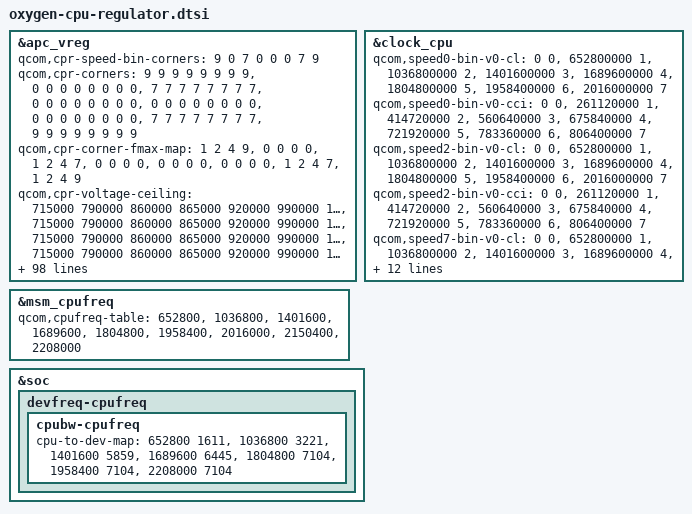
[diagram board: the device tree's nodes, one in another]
/* Copyright (c) 2020, The Linux Foundation. All rights reserved.
*  Copyright (c) 2020, Jebaitedneko.
*
* This program is free software; you can redistribute it and/or modify
* it under the terms of the GNU General Public License version 2 and
* only version 2 as published by the Free Software Foundation.
*
* This program is distributed in the hope that it will be useful,
* but WITHOUT ANY WARRANTY; without even the implied warranty of
* MERCHANTABILITY or FITNESS FOR A PARTICULAR PURPOSE.  See the
* GNU General Public License for more details.
*/

&apc_vreg {
	qcom,cpr-speed-bin-corners =
		<9 0 7 0 0 0 7 9>;
	qcom,cpr-corners =
		/* Speed bin 0 */
		<9 9 9 9 9 9 9 9>,

		/* Speed bin 1 */
		<0 0 0 0 0 0 0 0>,

		/* Speed bin 2 */
		<7 7 7 7 7 7 7 7>,

		/* Speed bin 3..5 */
		<0 0 0 0 0 0 0 0>,
		<0 0 0 0 0 0 0 0>,
		<0 0 0 0 0 0 0 0>,

		/* Speed bin 6 */
		<7 7 7 7 7 7 7 7>,

		/* Speed bin 7 */
		<9 9 9 9 9 9 9 9>;

	qcom,cpr-corner-fmax-map =
		/* Speed bin 0 */
		<1 2 4 9>,

		/* Speed bin 1 */
		<0 0 0 0>,

		/* Speed bin 2 */
		<1 2 4 7>,

		/* Speed bin 3..5 */
		<0 0 0 0>,
		<0 0 0 0>,
		<0 0 0 0>,

		/* Speed bin 6 */
		<1 2 4 7>,

		/* Speed bin 7 */
		<1 2 4 9>;

	qcom,cpr-voltage-ceiling =
		/* Speed bin 0 */
		<715000  790000 860000 865000 920000
			990000 1065000 1065000 1065000>,

		/* Speed bin 2 */
		<715000  790000 860000 865000 920000
			990000 1065000>,

		/* Speed bin 6 */
		<715000  790000 860000 865000 920000
			990000 1065000>,

		/* Speed bin 7 */
		<715000  790000 860000 865000 920000
			990000 1065000 1065000 1065000>;

	qcom,cpr-voltage-floor =
		/* Speed bin 0 */
		<500000  500000 500000 500000 500000
			500000  500000 500000 500000>,

		/* Speed bin 2 */
		<500000  500000 500000 500000 500000
			500000  500000>,

		/* Speed bin 6 */
		<500000  500000 500000 500000 500000
			500000  500000>,

		/* Speed bin 7 */
		<500000  500000 500000 500000 500000
			500000  500000 500000 500000>;

	qcom,cpr-floor-to-ceiling-max-range =
		/* Speed bin 0; CPR rev 0..7 */
			<    0     0     0     0     0
				0     0     0     0>,
			<50000 50000 50000 50000 50000
			50000 50000 50000 50000>,
			<50000 50000 50000 50000 50000
			50000 50000 50000 50000>,
			<50000 50000 50000 50000 50000
			50000 50000 50000 50000>,
			<50000 50000 50000 50000 50000
			50000 50000 50000 50000>,
			<50000 50000 50000 50000 50000
			50000 50000 50000 50000>,
			<50000 50000 50000 50000 50000
			50000 50000 50000 50000>,
			<50000 50000 50000 50000 50000
			50000 50000 50000 50000>,

		/* Speed bin 2; CPR rev 0..7 */
			<    0     0     0     0     0
				0     0>,
			<50000 50000 50000 50000 50000
			50000 50000>,
			<50000 50000 50000 50000 50000
			50000 50000>,
			<50000 50000 50000 50000 50000
			50000 50000>,
			<50000 50000 50000 50000 50000
			50000 50000>,
			<50000 50000 50000 50000 50000
			50000 50000>,
			<50000 50000 50000 50000 50000
			50000 50000>,
			<50000 50000 50000 50000 50000
			50000 50000>,

		/* Speed bin 6; CPR rev 0..7 */
			<    0     0     0     0     0
				0     0>,
			<50000 50000 50000 50000 50000
			50000 50000>,
			<50000 50000 50000 50000 50000
			50000 50000>,
			<50000 50000 50000 50000 50000
			50000 50000>,
			<50000 50000 50000 50000 50000
			50000 50000>,
			<50000 50000 50000 50000 50000
			50000 50000>,
			<50000 50000 50000 50000 50000
			50000 50000>,
			<50000 50000 50000 50000 50000
			50000 50000>,

		/* Speed bin 7; CPR rev 0..7 */
			<    0     0     0     0     0
				0     0     0     0>,
			<50000 50000 50000 50000 50000
			50000 50000 50000 50000>,
			<50000 50000 50000 50000 50000
			50000 50000 50000 50000>,
			<50000 50000 50000 50000 50000
			50000 50000 50000 50000>,
			<50000 50000 50000 50000 50000
			50000 50000 50000 50000>,
			<50000 50000 50000 50000 50000
			50000 50000 50000 50000>,
			<50000 50000 50000 50000 50000
			50000 50000 50000 50000>,
			<50000 50000 50000 50000 50000
			50000 50000 50000 50000>;

	qcom,cpr-misc-fuse-voltage-adjustment =
		/* Speed bin 0; misc fuse 0..1 */
		<    0     0     0     0      0
				0     0     0     0>,
		<    0     0 30000     0      0
				0     0     0     0>,

		/* Speed bin 2; misc fuse 0..1 */
		<    0     0     0     0      0
				0     0>,
		<    0     0 30000     0      0
				0     0>,

		/* Speed bin 6; misc fuse 0..1 */
		<    0     0     0     0      0
				0     0>,
		<    0     0 30000     0      0
				0     0>,

		/* Speed bin 7; misc fuse 0..1 */
		<    0     0     0     0      0
				0     0     0     0>,
		<    0     0 30000     0      0
				0     0     0     0>;

	qcom,mem-acc-voltage =
		/* Speed bin 0 */
		<1 1 2 2 2 2 2 2 2>,

		/* Speed bin 2 */
		<1 1 2 2 2 2 2>,

		/* Speed bin 6 */
		<1 1 2 2 2 2 2>,

		/* Speed bin 7 */
		<1 1 2 2 2 2 2 2 2>;

	qcom,corner-frequencies =
		/* Speed bin 0 */
		<652800000 1036800000 1401600000
		1689600000 1804800000 1958400000
		2016000000 2150400000 2208000000>,

		/* Speed bin 2 */
		<652800000 1036800000 1401600000
		1689600000 1804800000 1958400000
		2016000000>,

		/* Speed bin 6 */
		<652800000 1036800000 1401600000
		1689600000 1804800000 1958400000
		2016000000>,

		/* Speed bin 7 */
		<652800000 1036800000 1401600000
		1689600000 1804800000 1958400000
		2016000000 2150400000 2208000000>;

	qcom,cpr-open-loop-voltage-fuse-adjustment =
		/* Speed bin 0; CPR rev 0..7 */
		<     0      0      0     0>,
		< 25000      0   5000 40000>,
		< 25000      0   5000 40000>,
		< 25000      0   5000 40000>,
		<     0      0      0     0>,
		<     0      0      0     0>,
		<     0      0      0     0>,
		<     0      0      0     0>,

		/* Speed bin 1; CPR rev 0..7 */
		<     0      0      0     0>,
		<     0      0      0     0>,
		<     0      0      0     0>,
		<     0      0      0     0>,
		<     0      0      0     0>,
		<     0      0      0     0>,
		<     0      0      0     0>,
		<     0      0      0     0>,

		/* Speed bin 2; CPR rev 0..7 */
		<     0      0      0     0>,
		< 25000      0   5000 40000>,
		< 25000      0   5000 40000>,
		< 25000      0   5000 40000>,
		<     0      0      0     0>,
		<     0      0      0     0>,
		<     0      0      0     0>,
		<     0      0      0     0>,

		/* Speed bin 3; CPR rev 0..7 */
		<     0      0      0     0>,
		<     0      0      0     0>,
		<     0      0      0     0>,
		<     0      0      0     0>,
		<     0      0      0     0>,
		<     0      0      0     0>,
		<     0      0      0     0>,
		<     0      0      0     0>,

		/* Speed bin 4; CPR rev 0..7 */
		<     0      0      0     0>,
		<     0      0      0     0>,
		<     0      0      0     0>,
		<     0      0      0     0>,
		<     0      0      0     0>,
		<     0      0      0     0>,
		<     0      0      0     0>,
		<     0      0      0     0>,

		/* Speed bin 5; CPR rev 0..7 */
		<     0      0      0     0>,
		<     0      0      0     0>,
		<     0      0      0     0>,
		<     0      0      0     0>,
		<     0      0      0     0>,
		<     0      0      0     0>,
		<     0      0      0     0>,
		<     0      0      0     0>,

		/* Speed bin 6; CPR rev 0..7 */
		<     0      0      0     0>,
		< 25000      0   5000 40000>,
		< 25000      0   5000 40000>,
		< 25000      0   5000 40000>,
		<     0      0      0     0>,
		<     0      0      0     0>,
		<     0      0      0     0>,
		<     0      0      0     0>,

		/* Speed bin 7; CPR rev 0..7 */
		<     0      0      0     0>,
		< 25000      0   5000 40000>,
		< 25000      0   5000 40000>,
		< 25000      0   5000 40000>,
		<     0      0      0     0>,
		<     0      0      0     0>,
		<     0      0      0     0>,
		<     0      0      0     0>;

	qcom,cpr-closed-loop-voltage-fuse-adjustment =
		/* Speed bin 0; CPR rev 0..7 */
		<      0        0        0      0>,
		<  10000 (-15000)        0  25000>,
		<  10000 (-15000)        0  25000>,
		<(-5000) (-30000) (-15000)  10000>,
		<      0        0        0      0>,
		<      0        0        0      0>,
		<      0        0        0      0>,
		<      0        0        0      0>,

		/* Speed bin 1; CPR rev 0..7 */
		<      0        0        0      0>,
		<      0        0        0      0>,
		<      0        0        0      0>,
		<      0        0        0      0>,
		<      0        0        0      0>,
		<      0        0        0      0>,
		<      0        0        0      0>,
		<      0        0        0      0>,

		/* Speed bin 2; CPR rev 0..7 */
		<      0        0        0      0>,
		<  10000 (-15000)        0  25000>,
		<  10000 (-15000)        0  25000>,
		<(-5000) (-30000) (-15000)  10000>,
		<      0        0        0      0>,
		<      0        0        0      0>,
		<      0        0        0      0>,
		<      0        0        0      0>,

		/* Speed bin 3; CPR rev 0..7 */
		<      0        0        0      0>,
		<      0        0        0      0>,
		<      0        0        0      0>,
		<      0        0        0      0>,
		<      0        0        0      0>,
		<      0        0        0      0>,
		<      0        0        0      0>,
		<      0        0        0      0>,

		/* Speed bin 4; CPR rev 0..7 */
		<      0        0        0      0>,
		<      0        0        0      0>,
		<      0        0        0      0>,
		<      0        0        0      0>,
		<      0        0        0      0>,
		<      0        0        0      0>,
		<      0        0        0      0>,
		<      0        0        0      0>,

		/* Speed bin 5; CPR rev 0..7 */
		<      0        0        0      0>,
		<      0        0        0      0>,
		<      0        0        0      0>,
		<      0        0        0      0>,
		<      0        0        0      0>,
		<      0        0        0      0>,
		<      0        0        0      0>,
		<      0        0        0      0>,

		/* Speed bin 6; CPR rev 0..7 */
		<      0        0        0      0>,
		<  10000 (-15000)        0  25000>,
		<  10000 (-15000)        0  25000>,
		<(-5000) (-30000) (-15000)  10000>,
		<      0        0        0      0>,
		<      0        0        0      0>,
		<      0        0        0      0>,
		<      0        0        0      0>,

		/* Speed bin 7; CPR rev 0..7 */
		<      0        0        0      0>,
		<  10000 (-15000)        0  25000>,
		<  10000 (-15000)        0  25000>,
		<(-5000) (-30000) (-15000)  10000>,
		<      0        0        0      0>,
		<      0        0        0      0>,
		<      0        0        0      0>,
		<      0        0        0      0>;
	qcom,allow-aging-voltage-adjustment =
		/* Speed bin 0 */
		<0 0 0 1 1 1 1 1>,

		/* Speed bin 1 */
		<0 0 0 0 0 0 0 0>,

		/* Speed bin 2 */
		<0 0 0 1 1 1 1 1>,

		/* Speed bin 3..5 */
		<0 0 0 0 0 0 0 0>,
		<0 0 0 0 0 0 0 0>,
		<0 0 0 0 0 0 0 0>,

		/* Speed bin 6 */
		<0 0 0 1 1 1 1 1>,

		/* Speed bin 7 */
		<0 0 0 1 1 1 1 1>;
};

&clock_cpu {
	qcom,speed0-bin-v0-cl =
		<          0 0>,
		<  652800000 1>,
		< 1036800000 2>,
		< 1401600000 3>,
		< 1689600000 4>,
		< 1804800000 5>,
		< 1958400000 6>,
		< 2016000000 7>;
	qcom,speed0-bin-v0-cci =
		<          0 0>,
		<  261120000 1>,
		<  414720000 2>,
		<  560640000 3>,
		<  675840000 4>,
		<  721920000 5>,
		<  783360000 6>,
		<  806400000 7>;
	qcom,speed2-bin-v0-cl =
		<          0 0>,
		<  652800000 1>,
		< 1036800000 2>,
		< 1401600000 3>,
		< 1689600000 4>,
		< 1804800000 5>,
		< 1958400000 6>,
		< 2016000000 7>;
	qcom,speed2-bin-v0-cci =
		<          0 0>,
		<  261120000 1>,
		<  414720000 2>,
		<  560640000 3>,
		<  675840000 4>,
		<  721920000 5>,
		<  783360000 6>,
		<  806400000 7>;
	qcom,speed7-bin-v0-cl =
		<          0 0>,
		<  652800000 1>,
		< 1036800000 2>,
		< 1401600000 3>,
		< 1689600000 4>,
		< 1804800000 5>,
		< 1958400000 6>,
		< 2016000000 7>,
		< 2150400000 8>,
		< 2208000000 9>;
	qcom,speed7-bin-v0-cci =
		<          0 0>,
		<  261120000 1>,
		<  414720000 2>,
		<  560640000 3>,
		<  675840000 4>,
		<  721920000 5>,
		<  783360000 6>,
		<  806400000 7>,
		<  860160000 8>,
		<  883200000 9>;
	qcom,speed6-bin-v0-cl =
		<          0 0>,
		<  652800000 1>,
		< 1036800000 2>,
		< 1401600000 3>,
		< 1689600000 4>,
		< 1804800000 5>;
	qcom,speed6-bin-v0-cci =
		<          0 0>,
		<  261120000 1>,
		<  414720000 2>,
		<  560640000 3>,
		<  675840000 4>,
		<  721920000 5>;
};

&msm_cpufreq {
	qcom,cpufreq-table =
			<  652800 >,
			< 1036800 >,
			< 1401600 >,
			< 1689600 >,
			< 1804800 >,
			< 1958400 >,
			< 2016000 >,
			< 2150400 >,
			< 2208000 >;
};

&soc {
	devfreq-cpufreq {
		cpubw-cpufreq {
			cpu-to-dev-map =
					<  652800  1611>,
					< 1036800  3221>,
					< 1401600  5859>,
					< 1689600  6445>,
					< 1804800  7104>,
					< 1958400  7104>,
					< 2208000  7104>;
		};
	};
};
